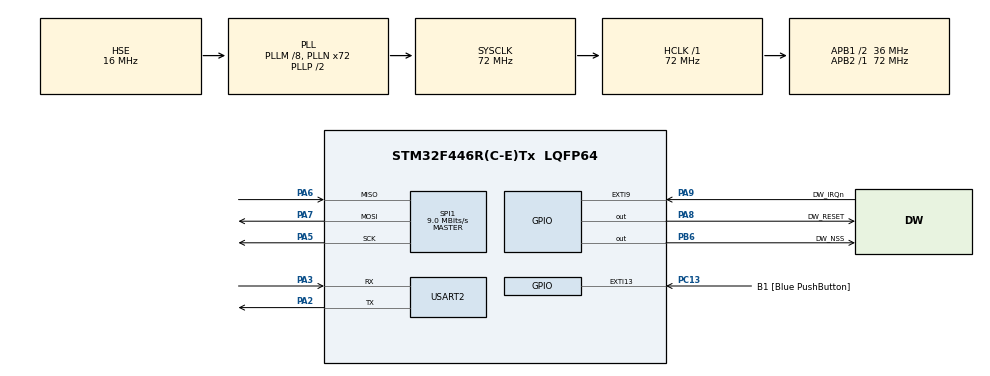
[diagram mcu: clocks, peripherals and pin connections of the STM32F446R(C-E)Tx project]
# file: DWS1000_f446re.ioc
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Mcu.Family=STM32F4
Mcu.Name=STM32F446R(C-E)Tx
Mcu.Package=LQFP64
NVIC.EXTI9_5_IRQn=true\:0\:0\:false\:false\:true\:true\:true
NVIC.PriorityGroup=NVIC_PRIORITYGROUP_0
PA13.GPIO_Label=TMS
PA13.Mode=Serial_Wire
PA13.Signal=SYS_JTMS-SWDIO
PA14.GPIO_Label=TCK
PA14.Mode=Serial_Wire
PA14.Signal=SYS_JTCK-SWCLK
PA2.Mode=Asynchronous
PA2.Signal=USART2_TX
PA3.Mode=Asynchronous
PA3.Signal=USART2_RX
PA5.Mode=Full_Duplex_Master
PA5.Signal=SPI1_SCK
PA6.Mode=Full_Duplex_Master
PA6.Signal=SPI1_MISO
PA7.Mode=Full_Duplex_Master
PA7.Signal=SPI1_MOSI
PA8.GPIO_Label=DW_RESET
PA8.Signal=GPIO_Output
PA9.GPIO_Label=DW_IRQn
PA9.Signal=GPXTI9
PB3.GPIO_Label=SWO
PB3.Signal=SYS_JTDO-SWO
PB6.GPIO_Label=DW_NSS
PB6.Signal=GPIO_Output
PC13.GPIO_Label=B1 [Blue PushButton]
PC13.GPIO_ModeDefaultEXTI=GPIO_MODE_IT_FALLING
PC13.Signal=GPXTI13
PC14-OSC32_IN.Mode=LSE-External-Oscillator
PC14-OSC32_IN.Signal=RCC_OSC32_IN
PC15-OSC32_OUT.Mode=LSE-External-Oscillator
PC15-OSC32_OUT.Signal=RCC_OSC32_OUT
PH0-OSC_IN.Mode=HSE-External-Oscillator
PH0-OSC_IN.Signal=RCC_OSC_IN
PH1-OSC_OUT.Mode=HSE-External-Oscillator
PH1-OSC_OUT.Signal=RCC_OSC_OUT
ProjectManager.HeapSize=0x200
ProjectManager.StackSize=0x400
ProjectManager.TargetToolchain=STM32CubeIDE
RCC.48MHZClocksFreq_Value=84000000
RCC.AHBFreq_Value=72000000
RCC.APB1CLKDivider=RCC_HCLK_DIV2
RCC.APB1Freq_Value=36000000
RCC.APB1TimFreq_Value=72000000
RCC.APB2Freq_Value=72000000
RCC.APB2TimFreq_Value=72000000
RCC.CortexFreq_Value=72000000
RCC.FLatency-AdvancedSettings=FLASH_LATENCY_2
RCC.HCLKFreq_Value=72000000
RCC.HSE_VALUE=16000000
RCC.HSI_VALUE=16000000
RCC.PLLM=8
RCC.PLLN=72
RCC.PLLSourceVirtual=RCC_PLLSOURCE_HSE
RCC.SYSCLKFreq_VALUE=72000000
RCC.SYSCLKSource=RCC_SYSCLKSOURCE_PLLCLK
RCC.USBFreq_Value=72000000
RCC.VCOOutputFreq_Value=144000000
SPI1.BaudRatePrescaler=SPI_BAUDRATEPRESCALER_8
SPI1.CalculateBaudRate=9.0 MBits/s
SPI1.Direction=SPI_DIRECTION_2LINES
SPI1.Mode=SPI_MODE_MASTER
SPI1.VirtualType=VM_MASTER
USART2.VirtualMode=VM_ASYNC
board=NUCLEO-F446RE

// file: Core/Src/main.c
/* USER CODE BEGIN Header */
/**
  ******************************************************************************
  * @file           : main.c
  * @brief          : Main program body
  ******************************************************************************
  * @attention
  *
  * <h2><center>&copy; Copyright (c) 2020 STMicroelectronics.
  * All rights reserved.</center></h2>
  *
  * This software component is licensed by ST under BSD 3-Clause license,
  * the "License"; You may not use this file except in compliance with the
  * License. You may obtain a copy of the License at:
  *                        opensource.org/licenses/BSD-3-Clause
  *
  ******************************************************************************
  */
/* USER CODE END Header */

#include "main.h"
#include "spi.h"
#include "usart.h"
#include "gpio.h"

/* USER CODE BEGIN Includes */
#include "port.h"
#include "stdio_.h"
/* USER CODE END Includes */

/* USER CODE BEGIN PV */
extern SPI_HandleTypeDef hspi1;
extern UART_HandleTypeDef huart2;

/* USER CODE END PV */

void SystemClock_Config(void);
/* USER CODE BEGIN PFP */

int __io_putchar(int ch)
{
//	__usart2.write((uint8_t*)ch, 1);
	HAL_UART_Transmit(&huart2, (uint8_t*)&ch, 1, 0xFFFF);
	return ch;
}
/* USER CODE END PFP */

/* USER CODE BEGIN 0 */
extern int dw_main(void);
/* USER CODE END 0 */

int main(void)
{

  /* MCU Configuration--------------------------------------------------------*/

  /* Reset of all peripherals, Initializes the Flash interface and the Systick. */
  HAL_Init();

  /* Configure the system clock */
  SystemClock_Config();

  /* Initialize all configured peripherals */
  MX_GPIO_Init();
  MX_USART2_UART_Init();
  MX_SPI1_Init();
  /* USER CODE BEGIN 2 */
  setup_DW1000RSTnIRQ(0);
//  stdio_init(&huart2);

  dw_main();
  /* USER CODE END 2 */

  /* Infinite loop */
  while (1)
  {

  }
}

void SystemClock_Config(void)
{
  RCC_OscInitTypeDef RCC_OscInitStruct = {0};
  RCC_ClkInitTypeDef RCC_ClkInitStruct = {0};

  /** Configure the main internal regulator output voltage
  */
  __HAL_RCC_PWR_CLK_ENABLE();
  __HAL_PWR_VOLTAGESCALING_CONFIG(PWR_REGULATOR_VOLTAGE_SCALE3);
  /** Initializes the CPU, AHB and APB busses clocks
  */
  RCC_OscInitStruct.OscillatorType = RCC_OSCILLATORTYPE_HSE;
  RCC_OscInitStruct.HSEState = RCC_HSE_ON;
  RCC_OscInitStruct.PLL.PLLState = RCC_PLL_ON;
  RCC_OscInitStruct.PLL.PLLSource = RCC_PLLSOURCE_HSE;
  RCC_OscInitStruct.PLL.PLLM = 8;
  RCC_OscInitStruct.PLL.PLLN = 72;
  RCC_OscInitStruct.PLL.PLLP = RCC_PLLP_DIV2;
  RCC_OscInitStruct.PLL.PLLQ = 2;
  RCC_OscInitStruct.PLL.PLLR = 2;
  if (HAL_RCC_OscConfig(&RCC_OscInitStruct) != HAL_OK)
  {
    Error_Handler();
  }
  /** Initializes the CPU, AHB and APB busses clocks
  */
  RCC_ClkInitStruct.ClockType = RCC_CLOCKTYPE_HCLK|RCC_CLOCKTYPE_SYSCLK
                              |RCC_CLOCKTYPE_PCLK1|RCC_CLOCKTYPE_PCLK2;
  RCC_ClkInitStruct.SYSCLKSource = RCC_SYSCLKSOURCE_PLLCLK;
  RCC_ClkInitStruct.AHBCLKDivider = RCC_SYSCLK_DIV1;
  RCC_ClkInitStruct.APB1CLKDivider = RCC_HCLK_DIV2;
  RCC_ClkInitStruct.APB2CLKDivider = RCC_HCLK_DIV1;

  if (HAL_RCC_ClockConfig(&RCC_ClkInitStruct, FLASH_LATENCY_2) != HAL_OK)
  {
    Error_Handler();
  }
}

void Error_Handler(void)
{
}

/************************ (C) COPYRIGHT STMicroelectronics *****END OF FILE****/
